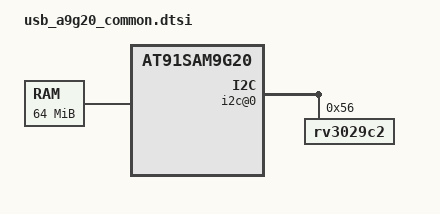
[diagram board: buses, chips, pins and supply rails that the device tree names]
/*
 * usb_a9g20.dts - Device Tree file for Caloa USB A9G20 board
 *
 *  Copyright (C) 2011 Jean-Christophe PLAGNIOL-VILLARD <plagnioj@jcrosoft.com>
 *
 * Licensed under GPLv2 or later.
 */

#include "at91sam9g20.dtsi"
#include "usb_a9260_common.dtsi"

/ {
	chosen {
		bootargs = "mem=64M console=ttyS0,115200 root=/dev/mtdblock5 rw rootfstype=ubifs";
	};

	memory {
		reg = <0x20000000 0x4000000>;
	};

	i2c@0 {
		rv3029c2@56 {
			compatible = "rv3029c2";
			reg = <0x56>;
		};
	};
};
